# ESP32S3_RADIO register map
File version: 0.1.0
Registers are 32-bit, read-write, no defined reset value unless marked. A register's access mark holds for its fields unless they carry their own. Offsets are from the block's base; [hi:lo] are bit positions; {n}, {i} and the like mark numbered series; <NAME> marks a mode.

## I2C_ANA_MST — Analog I2C master Base 0x6000e000. The HAL defines only 0x6000e040 (`I2C_MST_ANA_CONF0_REG`), bits 17 and 18 of 0x6000e044 (`ANA_CONFIG_REG`) and bit 16 of 0x6000e048 (`ANA_CONFIG2_REG`) (`modules/hal/espressif/components/soc/esp32s3/include/soc/regi2c_defs.h:12-26`). The names I2C0_CTRL and I2C1_CTRL are the ESP32-C6 HAL's for its command registers. **Frequency hop engine** (*speculative* field meanings, *decompile* flow). The S3 PHY can tune Wi-Fi channels with a hardware I2C sequencer in this block instead of a software calibration. `set_channel_rfpll_freq()` takes this path when `phy_param + 0x120` bit 5 is set, which `get_rf_freq_init()` does at PHY init after filling an 85-entry table (2400 to 2484 MHz, capacitor codes interpolated between calibrations at 2400 and 2464 MHz); otherwise it calls `set_rf_freq_offset()`. So `set_chanfreq()` on a channel frequency probably loads a table entry without a fresh VCO calibration (S3 `phy_rfpll.o`, `phy_hw_freq.o`). Its registers are I2C_ANA_MST_HOP_CTRL_REG, I2C_ANA_MST_R130_REG, I2C_ANA_MST_HOP_WDATA_REG, I2C_ANA_MST_R150_REG and I2C_ANA_MST_R170_REG.
Base 0x6000E000
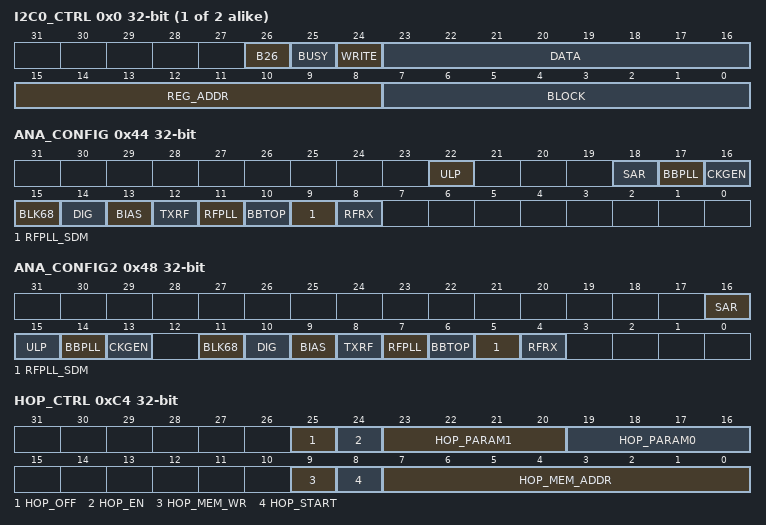
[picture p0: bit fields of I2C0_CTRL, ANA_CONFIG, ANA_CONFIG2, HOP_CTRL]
{0x0+4i} I2C{i}_CTRL (i=0..1) — Command word, master 0 (I2C0) and master 1 (I2C1) One command word per access, then poll I2C_ANA_MST_BUSY: block, register and bit 26 for a read (0x04000000 base), plus data and I2C_ANA_MST_WRITE for a write (0x05000000 base). The result is in bits 23:16. Evidence: *decompile* S3 ROM `rom_chip_i2c_readReg_org` (0x400354fc), `rom_chip_i2c_writeReg`; S3 `phy_i2c.o`
  [26] B26 — Unknown; always set.
  [25] BUSY ro — Busy, polled after each command.
  [24] WRITE — Set for a write.
  [23:16] DATA — Data to write, or the read result.
  [15:8] REG_ADDR — Register.
  [7:0] BLOCK
0x44 ANA_CONFIG — Readback enable, one bit per block The HAL's `ANA_CONFIG_REG`. Before a read the ROM writes the inverse of the block's bit (clear = readback enabled). Evidence: *decompile* ROM table at 0x3ff193dc (`rom_get_i2c_read_mask`), `rom_chip_i2c_readReg_org`
  [22] ULP — Block 0x61 (`i2c_ulp`); clear = readback enabled.
  [18] SAR — Block 0x69 (`i2c_sar`); clear = readback enabled.
  [17] BBPLL — Block 0x66 (`i2c_bbpll`); clear = readback enabled.
  [16] CKGEN — Block 0x65 (`i2c_ckgen`); clear = readback enabled.
  [15] BLK68 — Block 0x68; clear = readback enabled.
  [14] DIG — Block 0x6d (`i2c_dig_reg`); clear = readback enabled.
  [13] BIAS — Block 0x6a (`i2c_bias`); clear = readback enabled.
  [12] TXRF — Block 0x6b (`i2c_txrf`); clear = readback enabled.
  [11] RFPLL — Block 0x62 (`i2c_rfpll`); clear = readback enabled.
  [10] BBTOP — Block 0x67 (`i2c_bbtop`); clear = readback enabled.
  [9] RFPLL_SDM — Block 0x63 (`i2c_rfpll_sdm`); clear = readback enabled.
  [8] RFRX — Block 0x64 (`i2c_rfrx`); clear = readback enabled.
0x48 ANA_CONFIG2 — Master select, one bit per block The HAL's `ANA_CONFIG2_REG`. Bits 16:4 hold one master bit per block: set = master 0, clear = master 1. The ROM's `get_i2c_hostid()` writes bits 16:4 from 0x1ff40 (0x62 to 0x64 on master 1), libphy's from 0x1fe00 (0x62, 0x63, 0x64, 0x67, 0x6b), on every access. Evidence: *decompile* ROM table at 0x3ff193a8 (`rom_get_i2c_mst0_mask`), `rom_get_i2c_hostid` (0x400354bc); S3 `phy_i2c.o`
  [16] SAR — Block 0x69 (`i2c_sar`); 1 = master 0, 0 = master 1.
  [15] ULP — Block 0x61 (`i2c_ulp`); 1 = master 0, 0 = master 1.
  [14] BBPLL — Block 0x66 (`i2c_bbpll`); 1 = master 0, 0 = master 1.
  [13] CKGEN — Block 0x65 (`i2c_ckgen`); 1 = master 0, 0 = master 1.
  [11] BLK68 — Block 0x68; 1 = master 0, 0 = master 1.
  [10] DIG — Block 0x6d (`i2c_dig_reg`); 1 = master 0, 0 = master 1.
  [9] BIAS — Block 0x6a (`i2c_bias`); 1 = master 0, 0 = master 1.
  [8] TXRF — Block 0x6b (`i2c_txrf`); 1 = master 0, 0 = master 1.
  [7] RFPLL — Block 0x62 (`i2c_rfpll`); 1 = master 0, 0 = master 1.
  [6] BBTOP — Block 0x67 (`i2c_bbtop`); 1 = master 0, 0 = master 1.
  [5] RFPLL_SDM — Block 0x63 (`i2c_rfpll_sdm`); 1 = master 0, 0 = master 1.
  [4] RFRX — Block 0x64 (`i2c_rfrx`); 1 = master 0, 0 = master 1.
0xC4 HOP_CTRL — Frequency hop engine control (speculative) Evidence: *speculative* field meanings, *decompile* flow
  [25] HOP_OFF — 1 = hardware frequency setting off (`phy_dis_hw_set_freq()`).
  [24] HOP_EN — Enable, set at init.
  [23:20] HOP_PARAM1 — Init parameter, 4 at init.
  [19:16] HOP_PARAM0 — Init parameter, 2 at init.
  [9] HOP_MEM_WR wo — Table memory write strobe.
  [8] HOP_START wo — Start pulse.
  [7:0] HOP_MEM_ADDR — Table memory address (entry x 3 + word for writes).
0x130 R130 — Frequency hop engine module reset (speculative) Evidence: *speculative* field meanings, *decompile* flow
  [17] HOP_RST_N — Module reset, active low.
0x148 HOP_WDATA — Frequency hop engine table write data (speculative) Evidence: *speculative* field meanings, *decompile* flow
  [31:0] HOP_WDATA — Table write data: word 0 = `0x62:1` + (`0x62:2` image << 8), word 1 = the block 0x63 bytes.
0x150 R150 — Frequency hop engine channel index (speculative) Evidence: *speculative* field meanings, *decompile* flow
  [27:20] HOP_CHAN — Channel index (MHz - 2400).
0x170 R170 — Frequency hop engine current channel (speculative) Evidence: *speculative* field meanings, *decompile* flow
  [23:17] HOP_CUR_CHAN ro — Current channel, read back.
